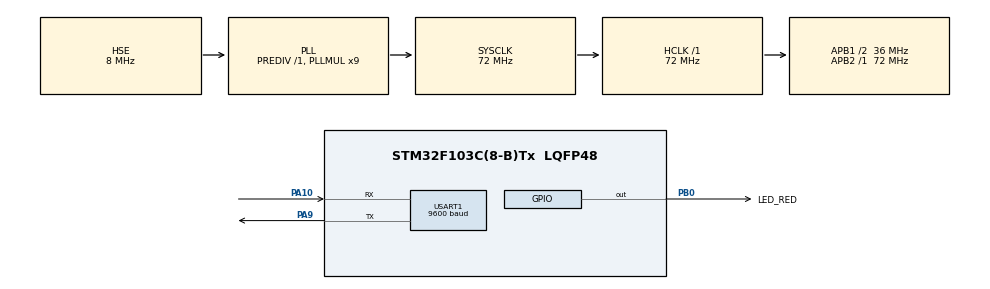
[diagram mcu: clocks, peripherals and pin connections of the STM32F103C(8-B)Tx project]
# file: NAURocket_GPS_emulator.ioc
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Mcu.Family=STM32F1
Mcu.Name=STM32F103C(8-B)Tx
Mcu.Package=LQFP48
NVIC.PriorityGroup=NVIC_PRIORITYGROUP_4
NVIC.TIM3_IRQn=true\:0\:0\:false\:false\:true\:true\:true
PA10.Mode=Asynchronous
PA10.Signal=USART1_RX
PA13.Mode=Serial_Wire
PA13.Signal=SYS_JTMS-SWDIO
PA14.Mode=Serial_Wire
PA14.Signal=SYS_JTCK-SWCLK
PA9.Mode=Asynchronous
PA9.Signal=USART1_TX
PB0.GPIO_Label=LED_RED
PB0.GPIO_ModeDefaultOutputPP=GPIO_MODE_OUTPUT_OD
PB0.Signal=GPIO_Output
PD0-OSC_IN.Mode=HSE-External-Oscillator
PD0-OSC_IN.Signal=RCC_OSC_IN
PD1-OSC_OUT.Mode=HSE-External-Oscillator
PD1-OSC_OUT.Signal=RCC_OSC_OUT
ProjectManager.HeapSize=0x200
ProjectManager.StackSize=0x400
ProjectManager.TargetToolchain=SW4STM32
RCC.AHBFreq_Value=72000000
RCC.APB1CLKDivider=RCC_HCLK_DIV2
RCC.APB1Freq_Value=36000000
RCC.APB1TimFreq_Value=72000000
RCC.APB2Freq_Value=72000000
RCC.APB2TimFreq_Value=72000000
RCC.HCLKFreq_Value=72000000
RCC.PLLMUL=RCC_PLL_MUL9
RCC.PLLSourceVirtual=RCC_PLLSOURCE_HSE
RCC.SYSCLKFreq_VALUE=72000000
RCC.SYSCLKSource=RCC_SYSCLKSOURCE_PLLCLK
RCC.USBFreq_Value=72000000
TIM3.Period=2000-1
TIM3.Prescaler=36000-1
USART1.BaudRate=9600
USART1.Mode=MODE_TX
USART1.VirtualMode=VM_ASYNC
VP_TIM3_VS_ClockSourceINT.Mode=Internal
board=custom

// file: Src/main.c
/* USER CODE BEGIN Header */
/**
  ******************************************************************************
  * @file           : main.c
  * @brief          : Main program body
  ******************************************************************************
  * @attention
  *
  * <h2><center>&copy; Copyright (c) 2019 STMicroelectronics.
  * All rights reserved.</center></h2>
  *
  * This software component is licensed by ST under BSD 3-Clause license,
  * the "License"; You may not use this file except in compliance with the
  * License. You may obtain a copy of the License at:
  *                        opensource.org/licenses/BSD-3-Clause
  *
  ******************************************************************************
  */
/* USER CODE END Header */

#include "main.h"
#include "tim.h"
#include "usart.h"
#include "gpio.h"

/* USER CODE BEGIN Includes */

	#include <string.h>
	#include <stdio.h>

/* USER CODE END Includes */

/* USER CODE BEGIN PD */

	#define	GPS_STRING_SIZE				200
	#define	GPS_STRING_QNT				9
	#define DELAY_BETWEEN_STRINGS_MS	25

/* USER CODE END PD */

/* USER CODE BEGIN PV */

	char GPS_String[GPS_STRING_QNT][GPS_STRING_SIZE];
	volatile uint8_t time_to_send_packet_flag = 0;

/* USER CODE END PV */

void SystemClock_Config(void);

int main(void)
{

  /* MCU Configuration--------------------------------------------------------*/

  /* Reset of all peripherals, Initializes the Flash interface and the Systick. */
  HAL_Init();

  /* Configure the system clock */
  SystemClock_Config();

  /* Initialize all configured peripherals */
  MX_GPIO_Init();
  MX_TIM3_Init();
  MX_USART1_UART_Init();
  /* USER CODE BEGIN 2 */

  HAL_TIM_Base_Start_IT(&htim3);
  HAL_TIM_Base_Start(&htim3);

  /* USER CODE END 2 */

	sprintf(GPS_String[0],"$GPRMC,093808.00,A,5029.75450,N,03046.52995,E,0.055,,180919,,,A*7C\r\n");
	sprintf(GPS_String[1],"$GPVTG,,T,,M,0.055,N,0.101,K,A*23\r\n");
	sprintf(GPS_String[2],"$GPGGA,093808.00,5029.75450,N,03046.52995,E,1,08,1.21,124.5,M,25.3,M,,*54\r\n");
	sprintf(GPS_String[3],"$GPGSA,A,3,20,21,27,10,32,08,18,11,,,,,1.97,1.21,1.55*0B\r\n");
	sprintf(GPS_String[4],"$GPGSV,4,1,15,01,09,283,25,04,46,183,14,08,57,285,27,10,70,069,30*7D\r\n");
	sprintf(GPS_String[5],"$GPGSV,4,2,15,11,17,298,25,14,16,164,,15,04,031,15,16,04,206,*79\r\n");
	sprintf(GPS_String[6],"$GPGSV,4,3,15,18,31,287,23,20,41,064,27,21,20,102,22,24,04,063,*78\r\n");
	sprintf(GPS_String[7],"$GPGSV,4,4,15,27,62,196,30,28,03,343,,32,34,148,28*4D\r\n");
	sprintf(GPS_String[8],"$GPGLL,5029.75450,N,03046.52995,E,093808.00,A,A*6D\r\n");

  /* Infinite loop */
  /* USER CODE BEGIN WHILE */
  while (1)
  {
	  if (time_to_send_packet_flag == 1)
	  {
		  for (int i=0; i<GPS_STRING_QNT; i++)
		  {
			HAL_UART_Transmit(&huart1, (uint8_t *)GPS_String[i], strlen(GPS_String[i]), 100);
			HAL_Delay(DELAY_BETWEEN_STRINGS_MS);
		  }
		  time_to_send_packet_flag = 0;
	  }

    /* USER CODE END WHILE */

  }
}

void SystemClock_Config(void)
{
  RCC_OscInitTypeDef RCC_OscInitStruct = {0};
  RCC_ClkInitTypeDef RCC_ClkInitStruct = {0};

  /** Initializes the CPU, AHB and APB busses clocks
  */
  RCC_OscInitStruct.OscillatorType = RCC_OSCILLATORTYPE_HSE;
  RCC_OscInitStruct.HSEState = RCC_HSE_ON;
  RCC_OscInitStruct.HSEPredivValue = RCC_HSE_PREDIV_DIV1;
  RCC_OscInitStruct.HSIState = RCC_HSI_ON;
  RCC_OscInitStruct.PLL.PLLState = RCC_PLL_ON;
  RCC_OscInitStruct.PLL.PLLSource = RCC_PLLSOURCE_HSE;
  RCC_OscInitStruct.PLL.PLLMUL = RCC_PLL_MUL9;
  if (HAL_RCC_OscConfig(&RCC_OscInitStruct) != HAL_OK)
  {
    Error_Handler();
  }
  /** Initializes the CPU, AHB and APB busses clocks
  */
  RCC_ClkInitStruct.ClockType = RCC_CLOCKTYPE_HCLK|RCC_CLOCKTYPE_SYSCLK
                              |RCC_CLOCKTYPE_PCLK1|RCC_CLOCKTYPE_PCLK2;
  RCC_ClkInitStruct.SYSCLKSource = RCC_SYSCLKSOURCE_PLLCLK;
  RCC_ClkInitStruct.AHBCLKDivider = RCC_SYSCLK_DIV1;
  RCC_ClkInitStruct.APB1CLKDivider = RCC_HCLK_DIV2;
  RCC_ClkInitStruct.APB2CLKDivider = RCC_HCLK_DIV1;

  if (HAL_RCC_ClockConfig(&RCC_ClkInitStruct, FLASH_LATENCY_2) != HAL_OK)
  {
    Error_Handler();
  }
}

void Error_Handler(void)
{
}

/************************ (C) COPYRIGHT STMicroelectronics *****END OF FILE****/
